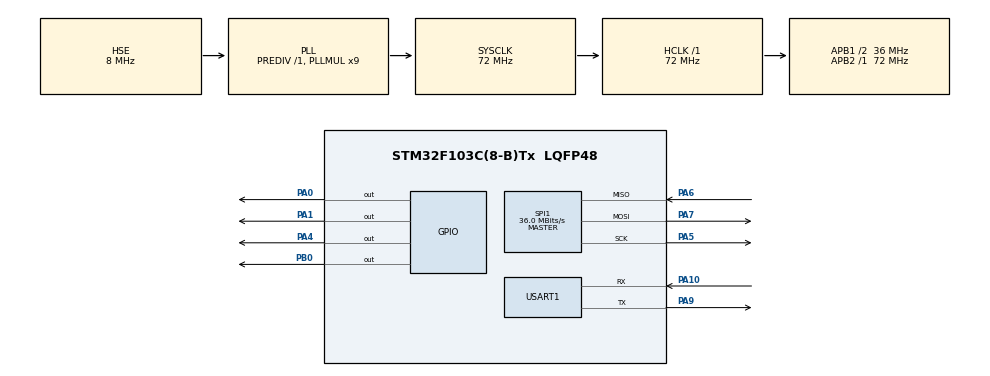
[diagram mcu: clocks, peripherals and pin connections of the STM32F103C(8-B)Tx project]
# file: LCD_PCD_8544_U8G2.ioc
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Mcu.Family=STM32F1
Mcu.Name=STM32F103C(8-B)Tx
Mcu.Package=LQFP48
NVIC.PriorityGroup=NVIC_PRIORITYGROUP_4
NVIC.USART1_IRQn=true\:0\:0\:false\:false\:true\:true\:true\:true
PA0-WKUP.Signal=GPIO_Output
PA1.Signal=GPIO_Output
PA10.Mode=Asynchronous
PA10.Signal=USART1_RX
PA13.Mode=Serial_Wire
PA13.Signal=SYS_JTMS-SWDIO
PA14.Mode=Serial_Wire
PA14.Signal=SYS_JTCK-SWCLK
PA4.Signal=GPIO_Output
PA5.Mode=Full_Duplex_Master
PA5.Signal=SPI1_SCK
PA6.Mode=Full_Duplex_Master
PA6.Signal=SPI1_MISO
PA7.Mode=Full_Duplex_Master
PA7.Signal=SPI1_MOSI
PA9.Mode=Asynchronous
PA9.Signal=USART1_TX
PB0.Signal=GPIO_Output
PC14-OSC32_IN.Mode=LSE-External-Oscillator
PC14-OSC32_IN.Signal=RCC_OSC32_IN
PC15-OSC32_OUT.Mode=LSE-External-Oscillator
PC15-OSC32_OUT.Signal=RCC_OSC32_OUT
PD0-OSC_IN.Mode=HSE-External-Oscillator
PD0-OSC_IN.Signal=RCC_OSC_IN
PD1-OSC_OUT.Mode=HSE-External-Oscillator
PD1-OSC_OUT.Signal=RCC_OSC_OUT
ProjectManager.HeapSize=0x200
ProjectManager.StackSize=0x400
ProjectManager.TargetToolchain=Makefile
RCC.AHBFreq_Value=72000000
RCC.APB1CLKDivider=RCC_HCLK_DIV2
RCC.APB1Freq_Value=36000000
RCC.APB1TimFreq_Value=72000000
RCC.APB2Freq_Value=72000000
RCC.APB2TimFreq_Value=72000000
RCC.HCLKFreq_Value=72000000
RCC.PLLMUL=RCC_PLL_MUL9
RCC.PLLSourceVirtual=RCC_PLLSOURCE_HSE
RCC.RTCClockSelection=RCC_RTCCLKSOURCE_LSE
RCC.SYSCLKFreq_VALUE=72000000
RCC.SYSCLKSource=RCC_SYSCLKSOURCE_PLLCLK
RCC.USBFreq_Value=72000000
SPI1.BaudRatePrescaler=SPI_BAUDRATEPRESCALER_2
SPI1.CalculateBaudRate=36.0 MBits/s
SPI1.Direction=SPI_DIRECTION_2LINES
SPI1.Mode=SPI_MODE_MASTER
SPI1.VirtualType=VM_MASTER
USART1.VirtualMode=VM_ASYNC
VP_RTC_VS_RTC_Activate.Mode=RTC_Enabled
board=custom

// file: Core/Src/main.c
/* USER CODE BEGIN Header */
/**
  ******************************************************************************
  * @file           : main.c
  * @brief          : Main program body
  ******************************************************************************
  * @attention
  *
  * Copyright (c) 2023 STMicroelectronics.
  * All rights reserved.
  *
  * This software is licensed under terms that can be found in the LICENSE file
  * in the root directory of this software component.
  * If no LICENSE file comes with this software, it is provided AS-IS.
  *
  ******************************************************************************
  */
/* USER CODE END Header */
#include "main.h"
#include "../u8g2/u8g2.h"

/* USER CODE BEGIN Includes */
static u8g2_t u8g2;
/* USER CODE BEGIN 0 */
uint32_t tick_main;
/* USER CODE END Includes */

 RTC_HandleTypeDef hrtc;

SPI_HandleTypeDef hspi1;

UART_HandleTypeDef huart1;

void SystemClock_Config(void);
static void MX_GPIO_Init(void);
static void MX_RTC_Init(void);
static void MX_SPI1_Init(void);
static void MX_USART1_UART_Init(void);
/* USER CODE BEGIN PFP */

uint8_t u8x8_stm32_gpio_and_delay(U8X8_UNUSED u8x8_t *u8x8,
                                  U8X8_UNUSED uint8_t msg,
                                  U8X8_UNUSED uint8_t arg_int,
                                  U8X8_UNUSED void *arg_ptr);

uint8_t u8x8_byte_4wire_hw_spi(u8x8_t *u8x8,
                              uint8_t msg,
                              uint8_t arg_int,
                              void *arg_ptr);

/* USER CODE END PFP */

int main(void)
{

  /* MCU Configuration--------------------------------------------------------*/

  /* Reset of all peripherals, Initializes the Flash interface and the Systick. */
  HAL_Init();

  /* Configure the system clock */
  SystemClock_Config();

  /* Initialize all configured peripherals */
  MX_GPIO_Init();
  MX_RTC_Init();
  MX_SPI1_Init();
  MX_USART1_UART_Init();
  /* USER CODE BEGIN 2 */
  HAL_GPIO_WritePin(GPIOB,GPIO_PIN_0,0);
  HAL_GPIO_WritePin(GPIOC,GPIO_PIN_13,1);
  /* USER CODE END 2 */
  /* USER CODE BEGIN 2 */
    u8g2_Setup_pcd8544_84x48_1(&u8g2, U8G2_R2,
                          u8x8_byte_4wire_hw_spi,
                          u8x8_stm32_gpio_and_delay);

   u8g2_InitDisplay(&u8g2);
   u8g2_SetPowerSave(&u8g2, 0);

  tick_main = HAL_GetTick();
  while (1)
  {
    if(HAL_GetTick() -  tick_main >= 100)
    {
      HAL_GPIO_TogglePin(GPIOC,GPIO_PIN_13);
      tick_main = HAL_GetTick();
    }
    /* USER CODE END WHILE */
    u8g2_FirstPage(&u8g2);
    do
    {
      u8g2_SetFont(&u8g2, u8g2_font_ncenB08_te);
      u8g2_DrawStr(&u8g2, 0, 15, "Hello World!");
      u8g2_DrawStr(&u8g2, 0, 30, "U8G2 ^^");
      u8g2_DrawCircle(&u8g2, 64, 40, 8, U8G2_DRAW_ALL);
    } while (u8g2_NextPage(&u8g2));
  }
}
//-------------------------------------

uint8_t u8x8_stm32_gpio_and_delay(U8X8_UNUSED u8x8_t *u8x8,
                                  U8X8_UNUSED uint8_t msg,
                                  U8X8_UNUSED uint8_t arg_int,
                                  U8X8_UNUSED void *arg_ptr){
  switch (msg)
  {
  case U8X8_MSG_GPIO_AND_DELAY_INIT:
    HAL_Delay(1);
    break;
  case U8X8_MSG_DELAY_MILLI:
    HAL_Delay(arg_int);
    break;
  case U8X8_MSG_GPIO_DC:
    HAL_GPIO_WritePin(LCD_GPIO_port, DC_PIN, arg_int);
    break;
  case U8X8_MSG_GPIO_RESET:
    HAL_GPIO_WritePin(LCD_GPIO_port, RST_PIN, arg_int);
    break;
  }
  return 1;
}

uint8_t u8x8_byte_4wire_hw_spi(u8x8_t *u8x8,
                              uint8_t msg,
                              uint8_t arg_int,
                              void *arg_ptr){
  switch (msg)
  {
  case U8X8_MSG_BYTE_SEND:
    HAL_SPI_Transmit(&hspi1, (uint8_t *) arg_ptr, arg_int, 1000);
    break;
  case U8X8_MSG_BYTE_INIT:
    break;
  case U8X8_MSG_BYTE_SET_DC:
    HAL_GPIO_WritePin(LCD_GPIO_port, DC_PIN, arg_int);
    break;
  case U8X8_MSG_BYTE_START_TRANSFER:
    break;
  case U8X8_MSG_BYTE_END_TRANSFER:
    break;
  default:
    return 0;
  }
  return 1;
}
void SystemClock_Config(void)
{
  RCC_OscInitTypeDef RCC_OscInitStruct = {0};
  RCC_ClkInitTypeDef RCC_ClkInitStruct = {0};
  RCC_PeriphCLKInitTypeDef PeriphClkInit = {0};

  /** Initializes the RCC Oscillators according to the specified parameters
  * in the RCC_OscInitTypeDef structure.
  */
  RCC_OscInitStruct.OscillatorType = RCC_OSCILLATORTYPE_HSE|RCC_OSCILLATORTYPE_LSE;
  RCC_OscInitStruct.HSEState = RCC_HSE_ON;
  RCC_OscInitStruct.HSEPredivValue = RCC_HSE_PREDIV_DIV1;
  RCC_OscInitStruct.LSEState = RCC_LSE_ON;
  RCC_OscInitStruct.HSIState = RCC_HSI_ON;
  RCC_OscInitStruct.PLL.PLLState = RCC_PLL_ON;
  RCC_OscInitStruct.PLL.PLLSource = RCC_PLLSOURCE_HSE;
  RCC_OscInitStruct.PLL.PLLMUL = RCC_PLL_MUL9;
  if (HAL_RCC_OscConfig(&RCC_OscInitStruct) != HAL_OK)
  {
    Error_Handler();
  }

  /** Initializes the CPU, AHB and APB buses clocks
  */
  RCC_ClkInitStruct.ClockType = RCC_CLOCKTYPE_HCLK|RCC_CLOCKTYPE_SYSCLK
                              |RCC_CLOCKTYPE_PCLK1|RCC_CLOCKTYPE_PCLK2;
  RCC_ClkInitStruct.SYSCLKSource = RCC_SYSCLKSOURCE_PLLCLK;
  RCC_ClkInitStruct.AHBCLKDivider = RCC_SYSCLK_DIV1;
  RCC_ClkInitStruct.APB1CLKDivider = RCC_HCLK_DIV2;
  RCC_ClkInitStruct.APB2CLKDivider = RCC_HCLK_DIV1;

  if (HAL_RCC_ClockConfig(&RCC_ClkInitStruct, FLASH_LATENCY_2) != HAL_OK)
  {
    Error_Handler();
  }
  PeriphClkInit.PeriphClockSelection = RCC_PERIPHCLK_RTC;
  PeriphClkInit.RTCClockSelection = RCC_RTCCLKSOURCE_LSE;
  if (HAL_RCCEx_PeriphCLKConfig(&PeriphClkInit) != HAL_OK)
  {
    Error_Handler();
  }
}

static void MX_RTC_Init(void)
{

  /** Initialize RTC Only
  */
  // hrtc.Instance = RTC;
  // hrtc.Init.AsynchPrediv = RTC_AUTO_1_SECOND;
  // hrtc.Init.OutPut = RTC_OUTPUTSOURCE_ALARM;
  // if (HAL_RTC_Init(&hrtc) != HAL_OK)
  // {
  //   Error_Handler();
  // }

}

static void MX_SPI1_Init(void)
{

  /* SPI1 parameter configuration*/
  hspi1.Instance = SPI1;
  hspi1.Init.Mode = SPI_MODE_MASTER;
  hspi1.Init.Direction = SPI_DIRECTION_2LINES;
  hspi1.Init.DataSize = SPI_DATASIZE_8BIT;
  hspi1.Init.CLKPolarity = SPI_POLARITY_LOW;
  hspi1.Init.CLKPhase = SPI_PHASE_1EDGE;
  hspi1.Init.NSS = SPI_NSS_SOFT;
  hspi1.Init.BaudRatePrescaler = SPI_BAUDRATEPRESCALER_2;
  hspi1.Init.FirstBit = SPI_FIRSTBIT_MSB;
  hspi1.Init.TIMode = SPI_TIMODE_DISABLE;
  hspi1.Init.CRCCalculation = SPI_CRCCALCULATION_DISABLE;
  hspi1.Init.CRCPolynomial = 10;
  if (HAL_SPI_Init(&hspi1) != HAL_OK)
  {
    Error_Handler();
  }

}

static void MX_USART1_UART_Init(void)
{

  huart1.Instance = USART1;
  huart1.Init.BaudRate = 115200;
  huart1.Init.WordLength = UART_WORDLENGTH_8B;
  huart1.Init.StopBits = UART_STOPBITS_1;
  huart1.Init.Parity = UART_PARITY_NONE;
  huart1.Init.Mode = UART_MODE_TX_RX;
  huart1.Init.HwFlowCtl = UART_HWCONTROL_NONE;
  huart1.Init.OverSampling = UART_OVERSAMPLING_16;
  if (HAL_UART_Init(&huart1) != HAL_OK)
  {
    Error_Handler();
  }

}

static void MX_GPIO_Init(void)
{
  GPIO_InitTypeDef GPIO_InitStruct = {0};

  /* GPIO Ports Clock Enable */
  __HAL_RCC_GPIOC_CLK_ENABLE();
  __HAL_RCC_GPIOD_CLK_ENABLE();
  __HAL_RCC_GPIOA_CLK_ENABLE();
  __HAL_RCC_GPIOB_CLK_ENABLE();

  /*Configure GPIO pin Output Level */
  HAL_GPIO_WritePin(GPIOA, GPIO_PIN_0|GPIO_PIN_1|GPIO_PIN_4, GPIO_PIN_RESET);

  /*Configure GPIO pin Output Level */
  HAL_GPIO_WritePin(GPIOB, GPIO_PIN_0, GPIO_PIN_RESET);

  /*Configure GPIO pins : PA0 PA1 PA4 */
  GPIO_InitStruct.Pin = GPIO_PIN_0|GPIO_PIN_1|GPIO_PIN_4;
  GPIO_InitStruct.Mode = GPIO_MODE_OUTPUT_PP;
  GPIO_InitStruct.Pull = GPIO_NOPULL;
  GPIO_InitStruct.Speed = GPIO_SPEED_FREQ_LOW;
  HAL_GPIO_Init(GPIOA, &GPIO_InitStruct);

  /*Configure GPIO pin : PB0 */
  GPIO_InitStruct.Pin = GPIO_PIN_0;
  GPIO_InitStruct.Mode = GPIO_MODE_OUTPUT_PP;
  GPIO_InitStruct.Pull = GPIO_NOPULL;
  GPIO_InitStruct.Speed = GPIO_SPEED_FREQ_LOW;
  HAL_GPIO_Init(GPIOB, &GPIO_InitStruct);

  /*Configure GPIO pin : PB0 */
  GPIO_InitStruct.Pin = GPIO_PIN_13;
  GPIO_InitStruct.Mode = GPIO_MODE_OUTPUT_PP;
  GPIO_InitStruct.Pull = GPIO_NOPULL;
  GPIO_InitStruct.Speed = GPIO_SPEED_FREQ_LOW;
  HAL_GPIO_Init(GPIOC, &GPIO_InitStruct);
}

void Error_Handler(void)
{
  __disable_irq();
  while (1)
  {
  }
}
